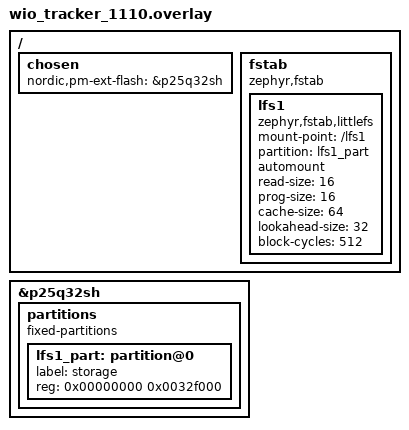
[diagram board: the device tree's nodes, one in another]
/*
 * SPDX-License-Identifier: Apache-2.0
 *
 * Copyright (c) 2022 Nordic Semiconductor ASA
 */

/ {
	chosen {
		nordic,pm-ext-flash = &p25q32sh;
	};
};

/delete-node/ &storage_partition;

/ {
	fstab {
		compatible = "zephyr,fstab";
		lfs1: lfs1 {
			compatible = "zephyr,fstab,littlefs";
			mount-point = "/lfs1";
			partition = <&lfs1_part>;
			automount;
			read-size = <16>;
			prog-size = <16>;
			cache-size = <64>;
			lookahead-size = <32>;
			block-cycles = <512>;
		};
	};
};

&p25q32sh {
	partitions {
		compatible = "fixed-partitions";
		#address-cells = <1>;
		#size-cells = <1>;

		lfs1_part: partition@0 {
			label = "storage";
			reg = <0x00000000 0x0032f000>;
		};
	};
};

// &uart0 {
// 	status = "disabled";
// };

// &i2c0 {
// 	status = "disabled";
// };

// &pwm0 {
// 	status = "disabled";
// };

